AUTOSAR XML (schema 00046)
package /VehicleProject
  system System
    system mapping System_MPPNG
      data-mappings:
        data-element=VcuRxMsg1_Sig0.VcuRxMsg1_Sig0, system-signal=VcuRxMsg1_Sig0
        data-element=VcuRxMsg1_Sig2.VcuRxMsg1_Sig2, system-signal=VcuRxMsg1_Sig2
        data-element=VcuRxMsg1_Sig1.VcuRxMsg1_Sig1, system-signal=VcuRxMsg1_Sig1
        data-element=VcuRxMsg2_Sig3.VcuRxMsg2_Sig3, system-signal=VcuRxMsg2_Sig3
        data-element=VcuRxMsg1_Sig3.VcuRxMsg1_Sig3, system-signal=VcuRxMsg1_Sig3
        data-element=VcuRxMsg2_Sig0.VcuRxMsg2_Sig0, system-signal=VcuRxMsg2_Sig0
        data-element=VcuRxMsg2_Sig2.VcuRxMsg2_Sig2, system-signal=VcuRxMsg2_Sig2
        data-element=VcuRxMsg2_Sig1.VcuRxMsg2_Sig1, system-signal=VcuRxMsg2_Sig1
        data-element=VcuTxMsg1_Sig1.VcuTxMsg1_Sig1, system-signal=VcuTxMsg1_Sig1
        data-element=VcuTxMsg2_Sig1.VcuTxMsg2_Sig1, system-signal=VcuTxMsg2_Sig1
        data-element=VcuTxMsg2_Sig2.VcuTxMsg2_Sig2, system-signal=VcuTxMsg2_Sig2
        data-element=VcuTxMsg1_Sig3.VcuTxMsg1_Sig3, system-signal=VcuTxMsg1_Sig3
        data-element=VcuTxMsg2_Sig0.VcuTxMsg2_Sig0, system-signal=VcuTxMsg2_Sig0
        data-element=VcuTxMsg2_Sig3.VcuTxMsg2_Sig3, system-signal=VcuTxMsg2_Sig3
        data-element=VcuTxMsg1_Sig2.VcuTxMsg1_Sig2, system-signal=VcuTxMsg1_Sig2
        data-element=VcuTxMsg1_Sig0.VcuTxMsg1_Sig0, system-signal=VcuTxMsg1_Sig0
    root-software-compositions:
      root sw composition prototype EcuSwComposition: software-composition=ECU_Composition
package /ECUCompositionTypes
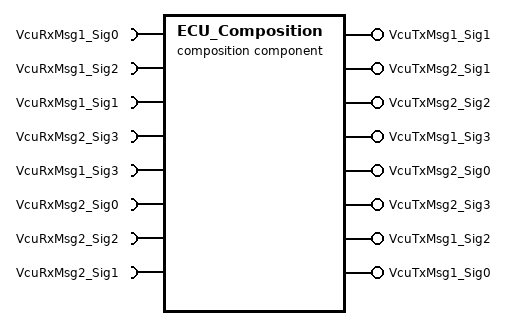
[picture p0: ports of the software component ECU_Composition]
  composition sw component type ECU_Composition
    8 x require port:
      VcuRxMsg1_Sig0: nonqueued-receiver-com-spec{data-element=VcuRxMsg1_Sig0, init-value=0}, required-interface=VcuRxMsg1_Sig0
      VcuRxMsg1_Sig2: nonqueued-receiver-com-spec{data-element=VcuRxMsg1_Sig2, init-value=0}, required-interface=VcuRxMsg1_Sig2
      VcuRxMsg1_Sig1: nonqueued-receiver-com-spec{data-element=VcuRxMsg1_Sig1, init-value=0}, required-interface=VcuRxMsg1_Sig1
      VcuRxMsg2_Sig3: nonqueued-receiver-com-spec{data-element=VcuRxMsg2_Sig3, init-value=0}, required-interface=VcuRxMsg2_Sig3
      VcuRxMsg1_Sig3: nonqueued-receiver-com-spec{data-element=VcuRxMsg1_Sig3, init-value=0}, required-interface=VcuRxMsg1_Sig3
      VcuRxMsg2_Sig0: nonqueued-receiver-com-spec{data-element=VcuRxMsg2_Sig0, init-value=0}, required-interface=VcuRxMsg2_Sig0
      VcuRxMsg2_Sig2: nonqueued-receiver-com-spec{data-element=VcuRxMsg2_Sig2, init-value=0}, required-interface=VcuRxMsg2_Sig2
      VcuRxMsg2_Sig1: nonqueued-receiver-com-spec{data-element=VcuRxMsg2_Sig1, init-value=0}, required-interface=VcuRxMsg2_Sig1
    8 x provide port:
      VcuTxMsg1_Sig1: nonqueued-sender-com-spec{data-element=VcuTxMsg1_Sig1, init-value=0}, provided-interface=VcuTxMsg1_Sig1
      VcuTxMsg2_Sig1: nonqueued-sender-com-spec{data-element=VcuTxMsg2_Sig1, init-value=0}, provided-interface=VcuTxMsg2_Sig1
      VcuTxMsg2_Sig2: nonqueued-sender-com-spec{data-element=VcuTxMsg2_Sig2, init-value=0}, provided-interface=VcuTxMsg2_Sig2
      VcuTxMsg1_Sig3: nonqueued-sender-com-spec{data-element=VcuTxMsg1_Sig3, init-value=0}, provided-interface=VcuTxMsg1_Sig3
      VcuTxMsg2_Sig0: nonqueued-sender-com-spec{data-element=VcuTxMsg2_Sig0, init-value=0}, provided-interface=VcuTxMsg2_Sig0
      VcuTxMsg2_Sig3: nonqueued-sender-com-spec{data-element=VcuTxMsg2_Sig3, init-value=0}, provided-interface=VcuTxMsg2_Sig3
      VcuTxMsg1_Sig2: nonqueued-sender-com-spec{data-element=VcuTxMsg1_Sig2, init-value=0}, provided-interface=VcuTxMsg1_Sig2
      VcuTxMsg1_Sig0: nonqueued-sender-com-spec{data-element=VcuTxMsg1_Sig0, init-value=0}, provided-interface=VcuTxMsg1_Sig0
    component SWC1: type=SWC1
    component PowerMng_SWC: type=PowerMng_SWC
    component Com_SWC: type=Com_SWC
    delegate Com_SWC.VcuRxMsg1_Sig0 <-> outer port VcuRxMsg1_Sig0
    delegate Com_SWC.VcuRxMsg1_Sig2 <-> outer port VcuRxMsg1_Sig2
    delegate Com_SWC.VcuRxMsg1_Sig1 <-> outer port VcuRxMsg1_Sig1
    delegate Com_SWC.VcuRxMsg2_Sig3 <-> outer port VcuRxMsg2_Sig3
    delegate Com_SWC.VcuRxMsg1_Sig3 <-> outer port VcuRxMsg1_Sig3
    delegate Com_SWC.VcuRxMsg2_Sig0 <-> outer port VcuRxMsg2_Sig0
    delegate Com_SWC.VcuRxMsg2_Sig2 <-> outer port VcuRxMsg2_Sig2
    delegate Com_SWC.VcuRxMsg2_Sig1 <-> outer port VcuRxMsg2_Sig1
    delegate Com_SWC.VcuTxMsg1_Sig1 <-> outer port VcuTxMsg1_Sig1
    delegate Com_SWC.VcuTxMsg2_Sig1 <-> outer port VcuTxMsg2_Sig1
    delegate Com_SWC.VcuTxMsg2_Sig2 <-> outer port VcuTxMsg2_Sig2
    delegate Com_SWC.VcuTxMsg1_Sig3 <-> outer port VcuTxMsg1_Sig3
    delegate Com_SWC.VcuTxMsg2_Sig0 <-> outer port VcuTxMsg2_Sig0
    delegate Com_SWC.VcuTxMsg2_Sig3 <-> outer port VcuTxMsg2_Sig3
    delegate Com_SWC.VcuTxMsg1_Sig2 <-> outer port VcuTxMsg1_Sig2
    delegate Com_SWC.VcuTxMsg1_Sig0 <-> outer port VcuTxMsg1_Sig0
package /EndToEndProtections
  end to end protection set EndToEndProtectionSet
